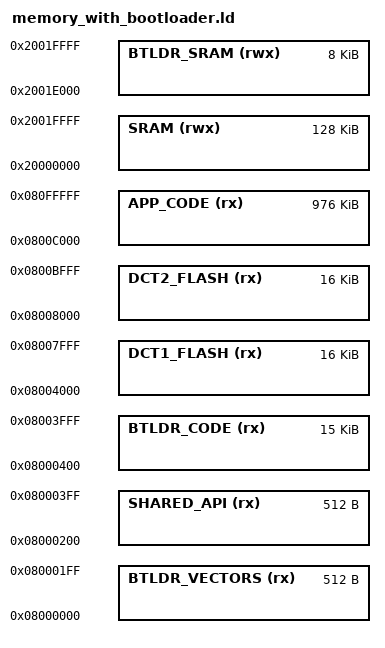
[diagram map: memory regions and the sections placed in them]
/*
 * Copyright (c) 2015 Broadcom
 * All rights reserved.
 *
 * Redistribution and use in source and binary forms, with or without modification,
 * are permitted provided that the following conditions are met:
 *
 * 1. Redistributions of source code must retain the above copyright notice, this
 * list of conditions and the following disclaimer.
 *
 * 2. Redistributions in binary form must reproduce the above copyright notice, this
 * list of conditions and the following disclaimer in the documentation and/or
 * other materials provided with the distribution.
 *
 * 3. Neither the name of Broadcom nor the names of other contributors to this
 * software may be used to endorse or promote products derived from this software
 * without specific prior written permission.
 *
 * 4. This software may not be used as a standalone product, and may only be used as
 * incorporated in your product or device that incorporates Broadcom wireless connectivity
 * products and solely for the purpose of enabling the functionalities of such Broadcom products.
 *
 *
 * THIS SOFTWARE IS PROVIDED BY THE COPYRIGHT HOLDERS AND CONTRIBUTORS "AS IS" AND
 * ANY WARRANTIES OF ANY KIND, EXPRESS OR IMPLIED, INCLUDING, BUT NOT LIMITED TO, THE IMPLIED
 * WARRANTIES OF MERCHANTABILITY, FITNESS FOR A PARTICULAR PURPOSE AND NON-INFRINGEMENT, ARE
 * DISCLAIMED. IN NO EVENT SHALL THE COPYRIGHT HOLDER OR CONTRIBUTORS BE LIABLE FOR
 * ANY DIRECT, INDIRECT, INCIDENTAL, SPECIAL, EXEMPLARY, OR CONSEQUENTIAL DAMAGES
 * (INCLUDING, BUT NOT LIMITED TO, PROCUREMENT OF SUBSTITUTE GOODS OR SERVICES;
 * LOSS OF USE, DATA, OR PROFITS; OR BUSINESS INTERRUPTION) HOWEVER CAUSED AND ON
 * ANY THEORY OF LIABILITY, WHETHER IN CONTRACT, STRICT LIABILITY, OR TORT
 * (INCLUDING NEGLIGENCE OR OTHERWISE) ARISING IN ANY WAY OUT OF THE USE OF THIS
 * SOFTWARE, EVEN IF ADVISED OF THE POSSIBILITY OF SUCH DAMAGE.
 */

MEMORY
{
    BTLDR_VECTORS    (rx)  : ORIGIN = 0x08000000, LENGTH = 512
    SHARED_API       (rx)  : ORIGIN = 0x08000200, LENGTH = 512
    BTLDR_CODE       (rx)  : ORIGIN = 0x08000400, LENGTH = 15K
    DCT1_FLASH       (rx)  : ORIGIN = 0x08004000, LENGTH = 16K
    DCT2_FLASH       (rx)  : ORIGIN = 0x08008000, LENGTH = 16K
    APP_CODE         (rx)  : ORIGIN = 0x0800C000, LENGTH = 0xF4000  /* 976K */
    SRAM             (rwx) : ORIGIN = 0x20000000, LENGTH = 128K
    BTLDR_SRAM       (rwx) : ORIGIN = 0x2001E000, LENGTH = 8k       /* Boot loader stack at the end. */
}
